# R7FA8M1AH register map
Vendor: Renesas; Series: RA8; File version: 1.2
CPU: CM85 r0p0, little endian, MPU, FPU, VTOR, 4 interrupt priority bits
Registers are 32-bit, read-write, reset 0x0 unless marked. A register's access mark holds for its fields unless they carry their own. Offsets are from the block's base; [hi:lo] are bit positions; {n}, {i} and the like mark numbered series; 'fields as' and 'values as' point back to an identical list; <NAME> marks a mode.

## I3C (part 3 of 4) — I2C I3C unified IP
Base 0x4035F000
Same registers: I3C_NS 0x5035F000
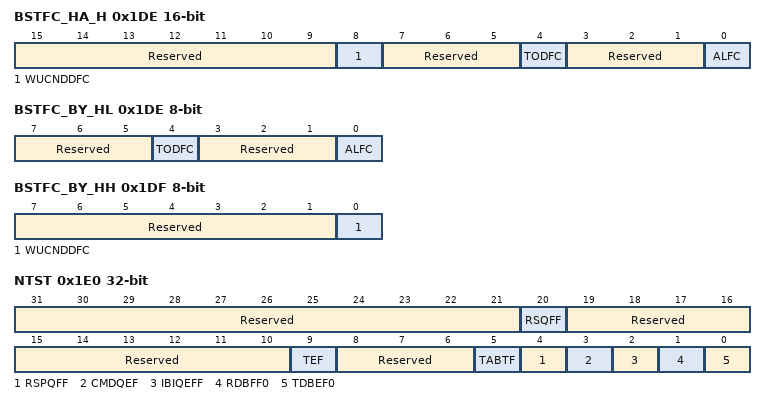
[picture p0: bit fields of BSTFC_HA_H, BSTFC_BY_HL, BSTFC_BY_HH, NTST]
0x1DE BSTFC_HA_H 16-bit wo — Bus Status Force Register
  [15:9] Reserved — The write value should be 0000000.
  [8] WUCNDDFC — Wake-Up Condition Detection Force
    0=not Force Wake-Up Condition Detection Interrupt for software testing; 1=Force Wake-Up Condition Detection Interrupt for software testing
  [7:5] Reserved — The write value should be 000.
  [4] TODFC — Timeout Detection Force
    0=not Force Timeout Detection Interrupt for software testing; 1=Force Timeout Detection Interrupt for software testing
  [3:1] Reserved — The write value should be 000.
  [0] ALFC — Arbitration Lost Force
    0=not Force Arbitration Lost Interrupt for software testing; 1=Force Arbitration Lost Interrupt for software testing
0x1DE BSTFC_BY_HL 8-bit wo — Bus Status Force Register
  [7:5] Reserved — The write value should be 000.
  [4] TODFC — Timeout Detection Force
    values as BSTFC_HA_H.TODFC
  [3:1] Reserved — The write value should be 000.
  [0] ALFC — Arbitration Lost Force
    values as BSTFC_HA_H.ALFC
0x1DF BSTFC_BY_HH 8-bit wo — Bus Status Force Register
  [7:1] Reserved — The write value should be 0000000.
  [0] WUCNDDFC — Wake-Up Condition Detection Force
    values as BSTFC_HA_H.WUCNDDFC
0x1E0 NTST — Normal Transfer Status Register
  [31:21] Reserved — These bits are read as 00000000000. The write value should be 00000000000.
  [20] RSQFF read-modifies — Normal Receive Status Queue Full Flag
    0=The number of Receive Status Queue entries is <= the NRQTHCTL.RSQTH threshold; 1=The number of Receive Status Queue entries is > the NRQTHCTL.RSQTH threshold
  [19:10] Reserved — These bits are read as 0000000000. The write value should be 0000000000.
  [9] TEF read-modifies — Normal Transfer Error Flag
    0=Transfer Error does not occur; 1=Transfer Error occurs
  [8:6] Reserved — These bits are read as 000. The write value should be 000.
  [5] TABTF read-modifies — Normal Transfer Abort Flag
    0=Transfer Abort does not occur; 1=Transfer Abort occur
  [4] RSPQFF read-modifies — Normal Response Queue Full Flag
    0=The number of Response Queue entries is <= the NQTHCTL.RSPQTH threshold; 1=The number of Response Queue entries is > the NQTHCTL.RSPQTH threshold
  [3] CMDQEF read-modifies — Normal Command Queue Empty Flag
    0=The number of Command Queue empties is < the Command Queue size; 1=The number of Command Queue empties is the Command Queue size; 0=The number of Command Queue empties is < the NQTHCTL.CMDQTH threshold; 1=The number of Command Queue empties is >= the NQTHCTL.CMDQTH threshold
  [2] IBIQEFF read-modifies — Normal IBI Queue Empty/Full Flag
    0=The number of IBI Status Queue entries is <= the NQTHCTL.IBIQTH threshold; 1=The number of IBI Status Queue entries is > the NQTHCTL.IBIQTH threshold; 0=The number of IBI Data Buffer empties is < the IBI Data Buffer size; 1=The number of IBI Data Buffer empties is the IBI Data Buffer size; 0=The number of IBI Data Buffer empties is < the NQTHCTL.IBIQTH threshold; 1=The number of IBI Data Buffer empties is >= the NQTHCTL.IBIQTH threshold
  [1] RDBFF0 read-modifies — Normal Rx Data Buffer Full Flag 0
    0=Normal Rx Data Buffer0 contains no receive data; 1=Normal Rx Data Buffer0 contains receive data; 0=The number of entries in the Normal Rx Data Buffer 0 is < the NTBTHCTL0.RXDBTH[2:0] threshold; 1=The number of entries in the Normal Rx Data Buffer 0 is >= the NTBTHCTL0.RXDBTH[2:0] threshold
  [0] TDBEF0 read-modifies — Normal Tx Data Buffer Empty Flag 0
    0=Normal Tx Data Buffer 0 contains transmit data; 1=Normal Tx Data Buffer 0 contains no transmit data; 0=The number of empties in the Normal Tx Data Buffer 0 is < the NTBTHCTL0.TXDBTH[2:0] threshold; 1=The number of empties in the Normal Tx Data Buffer 0 is >= the NTBTHCTL0.TXDBTH[2:0] threshold
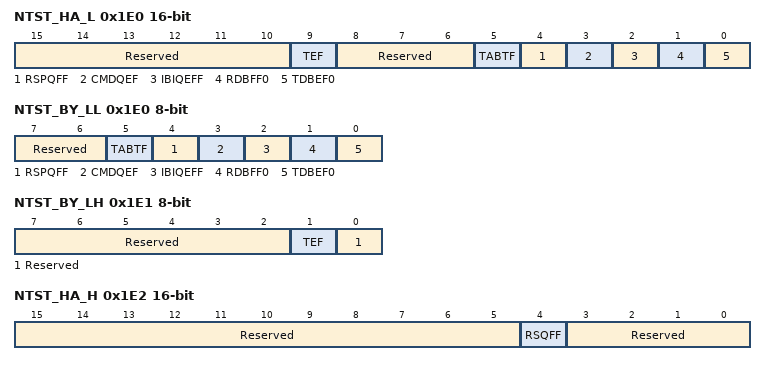
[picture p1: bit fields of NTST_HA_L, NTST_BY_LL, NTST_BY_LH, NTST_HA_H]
0x1E0 NTST_HA_L 16-bit — Normal Transfer Status Register
  [15:10] Reserved — These bits are read as 000000. The write value should be 000000.
  [9] TEF read-modifies — Normal Transfer Error Flag
    0=Transfer Error does not occur; 1=Transfer Error occurs
  [8:6] Reserved — These bits are read as 000. The write value should be 000.
  [5] TABTF read-modifies — Normal Transfer Abort Flag
    0=Transfer Abort does not occur; 1=Transfer Abort occur
  [4] RSPQFF read-modifies — Normal Response Queue Full Flag
    values as NTST.RSPQFF
  [3] CMDQEF read-modifies — Normal Command Queue Empty Flag
    values as NTST.CMDQEF
  [2] IBIQEFF read-modifies — Normal IBI Queue Empty/Full Flag
    values as NTST.IBIQEFF
  [1] RDBFF0 read-modifies — Normal Rx Data Buffer Full Flag 0
    values as NTST.RDBFF0
  [0] TDBEF0 read-modifies — Normal Tx Data Buffer Empty Flag 0
    values as NTST.TDBEF0
0x1E0 NTST_BY_LL 8-bit — Normal Transfer Status Register
  [7:6] Reserved — These bits are read as 00. The write value should be 00.
  [5] TABTF read-modifies — Normal Transfer Abort Flag
    0=Transfer Abort does not occur; 1=Transfer Abort occur
  [4] RSPQFF read-modifies — Normal Response Queue Full Flag
    values as NTST.RSPQFF
  [3] CMDQEF read-modifies — Normal Command Queue Empty Flag
    values as NTST.CMDQEF
  [2] IBIQEFF read-modifies — Normal IBI Queue Empty/Full Flag
    values as NTST.IBIQEFF
  [1] RDBFF0 read-modifies — Normal Rx Data Buffer Full Flag 0
    values as NTST.RDBFF0
  [0] TDBEF0 read-modifies — Normal Tx Data Buffer Empty Flag 0
    values as NTST.TDBEF0
0x1E1 NTST_BY_LH 8-bit — Normal Transfer Status Register
  [7:2] Reserved — These bits are read as 000000. The write value should be 000000.
  [1] TEF read-modifies — Normal Transfer Error Flag
    0=Transfer Error does not occur; 1=Transfer Error occurs
  [0] Reserved — This bit is read as 0. The write value should be 0.
0x1E2 NTST_HA_H 16-bit — Normal Transfer Status Register
  [15:5] Reserved — These bits are read as 00000000000. The write value should be 00000000000.
  [4] RSQFF read-modifies — Normal Receive Status Queue Full Flag
    values as NTST.RSQFF
  [3:0] Reserved — These bits are read as 0000. The write value should be 0000.
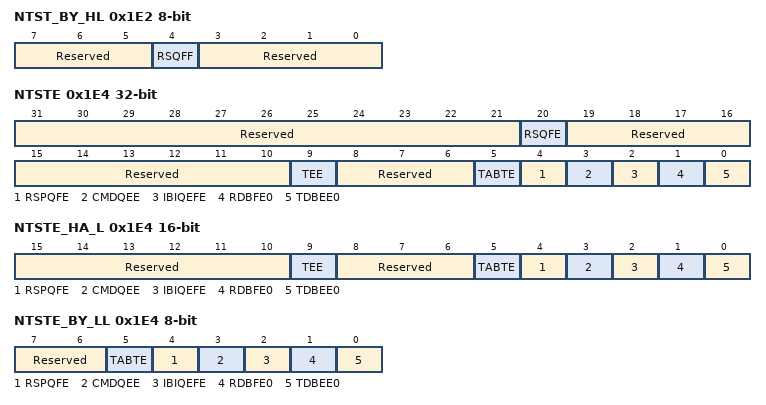
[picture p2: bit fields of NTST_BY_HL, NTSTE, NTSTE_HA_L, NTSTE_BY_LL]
0x1E2 NTST_BY_HL 8-bit — Normal Transfer Status Register
  [7:5] Reserved — These bits are read as 000. The write value should be 000.
  [4] RSQFF read-modifies — Normal Receive Status Queue Full Flag
    values as NTST.RSQFF
  [3:0] Reserved — These bits are read as 0000. The write value should be 0000.
0x1E4 NTSTE — Normal Transfer Status Enable Register
  [31:21] Reserved — These bits are read as 00000000000. The write value should be 00000000000.
  [20] RSQFE — Normal Receive Status Queue Full Enable
    0=Disables Receive Status Buffer Full Interrupt Status logging; 1=Enables Receive Status Buffer Full Interrupt Status logging
  [19:10] Reserved — These bits are read as 0000000000. The write value should be 0000000000.
  [9] TEE — Normal Transfer Error Enable
    0=Disables Transfer Error Interrupt Status logging; 1=Enables Transfer Error Interrupt Status logging
  [8:6] Reserved — These bits are read as 000. The write value should be 000.
  [5] TABTE — Normal Transfer Abort Enable
    0=Disables Transfer Abort Interrupt Status logging; 1=Enables Transfer Abort Interrupt Status logging
  [4] RSPQFE — Normal Response Queue Full Enable
    0=Disables Response Buffer Full Interrupt Status logging; 1=Enables Response Buffer Full Interrupt Status logging
  [3] CMDQEE — Normal Command Queue Empty Enable
    0=Disables Command Buffer Empty Interrupt Status logging; 1=Enables Command Buffer Empty Interrupt Status logging
  [2] IBIQEFE — Normal IBI Queue Empty/Full Enable
    0=Disables IBI Status Buffer Empty/Full Interrupt Status logging; 1=Enables IBI Status Buffer Empty/Full Interrupt Status logging
  [1] RDBFE0 — Normal Rx Data Buffer Full Enable 0
    0=Disables Rx0 Data Buffer Full Interrupt Status logging; 1=Enables Rx0 Data Buffer Full Interrupt Status logging
  [0] TDBEE0 — Normal Tx Data Buffer Empty Enable 0
    0=Disables Tx0 Data Buffer Empty Interrupt Status logging; 1=Enables Tx0 Data Buffer Empty Interrupt Status logging
0x1E4 NTSTE_HA_L 16-bit — Normal Transfer Status Enable Register
  [15:10] Reserved — These bits are read as 000000. The write value should be 000000.
  [9] TEE — Normal Transfer Error Enable
    values as NTSTE.TEE
  [8:6] Reserved — These bits are read as 000. The write value should be 000.
  [5] TABTE — Normal Transfer Abort Enable
    values as NTSTE.TABTE
  [4] RSPQFE — Normal Response Queue Full Enable
    values as NTSTE.RSPQFE
  [3] CMDQEE — Normal Command Queue Empty Enable
    values as NTSTE.CMDQEE
  [2] IBIQEFE — Normal IBI Queue Empty/Full Enable
    values as NTSTE.IBIQEFE
  [1] RDBFE0 — Normal Rx Data Buffer Full Enable 0
    values as NTSTE.RDBFE0
  [0] TDBEE0 — Normal Tx Data Buffer Empty Enable 0
    values as NTSTE.TDBEE0
0x1E4 NTSTE_BY_LL 8-bit — Normal Transfer Status Enable Register
  [7:6] Reserved — These bits are read as 00. The write value should be 00.
  [5] TABTE — Normal Transfer Abort Enable
    values as NTSTE.TABTE
  [4] RSPQFE — Normal Response Queue Full Enable
    values as NTSTE.RSPQFE
  [3] CMDQEE — Normal Command Queue Empty Enable
    values as NTSTE.CMDQEE
  [2] IBIQEFE — Normal IBI Queue Empty/Full Enable
    values as NTSTE.IBIQEFE
  [1] RDBFE0 — Normal Rx Data Buffer Full Enable 0
    values as NTSTE.RDBFE0
  [0] TDBEE0 — Normal Tx Data Buffer Empty Enable 0
    values as NTSTE.TDBEE0
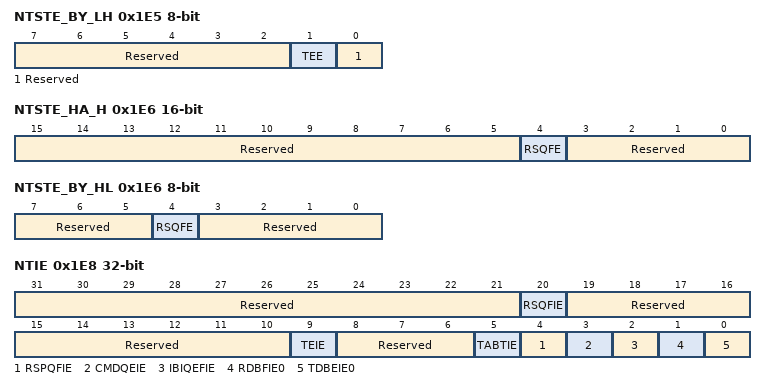
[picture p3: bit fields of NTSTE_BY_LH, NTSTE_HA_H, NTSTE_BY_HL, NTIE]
0x1E5 NTSTE_BY_LH 8-bit — Normal Transfer Status Enable Register
  [7:2] Reserved — These bits are read as 000000. The write value should be 000000.
  [1] TEE — Normal Transfer Error Enable
    values as NTSTE.TEE
  [0] Reserved — This bit is read as 0. The write value should be 0.
0x1E6 NTSTE_HA_H 16-bit — Normal Transfer Status Enable Register
  [15:5] Reserved — These bits are read as 00000000000. The write value should be 00000000000.
  [4] RSQFE — Normal Receive Status Queue Full Enable
    values as NTSTE.RSQFE
  [3:0] Reserved — These bits are read as 0000. The write value should be 0000.
0x1E6 NTSTE_BY_HL 8-bit — Normal Transfer Status Enable Register
  [7:5] Reserved — These bits are read as 000. The write value should be 000.
  [4] RSQFE — Normal Receive Status Queue Full Enable
    values as NTSTE.RSQFE
  [3:0] Reserved — These bits are read as 0000. The write value should be 0000.
0x1E8 NTIE — Normal Transfer Interrupt Enable Register
  [31:21] Reserved — These bits are read as 00000000000. The write value should be 00000000000.
  [20] RSQFIE — Normal Receive Status Queue Full Interrupt Enable
    0=Disables Receive Status Buffer Full Interrupt Signal; 1=Enables Receive Status Buffer Full Interrupt Signal
  [19:10] Reserved — These bits are read as 0000000000. The write value should be 0000000000.
  [9] TEIE — Normal Transfer Error Interrupt Enable
    0=Disables Transfer Error Interrupt Signal; 1=Enables Transfer Error Interrupt Signal
  [8:6] Reserved — These bits are read as 000. The write value should be 000.
  [5] TABTIE — Normal Transfer Abort Interrupt Enable
    0=Disables Transfer Abort Interrupt Signal; 1=Enables Transfer Abort Interrupt Signal
  [4] RSPQFIE — Normal Response Queue Full Interrupt Enable
    0=Disables Response Buffer Full Interrupt Signal; 1=Enables Response Buffer Full Interrupt Signal
  [3] CMDQEIE — Normal Command Queue Empty Interrupt Enable
    0=Disables Command Buffer Empty Interrupt Signal; 1=Enables Command Buffer Empty Interrupt Signal
  [2] IBIQEFIE — Normal IBI Queue Empty/Full Interrupt Enable
    0=Disables IBI Status Buffer Empty/Full Interrupt Signal; 1=Enables IBI Status Buffer Empty/Full Interrupt Signal
  [1] RDBFIE0 — Normal Rx Data Buffer Full Interrupt Enable 0
    0=Disables Rx0 Data Buffer Full Interrupt Signal; 1=Enables Rx0 Data Buffer Full Interrupt Signal
  [0] TDBEIE0 — Normal Tx Data Buffer Empty Interrupt Enable 0
    0=Disables Tx0 Data Buffer Empty Interrupt Signal; 1=Enables Tx0 Data Buffer Empty Interrupt Signal
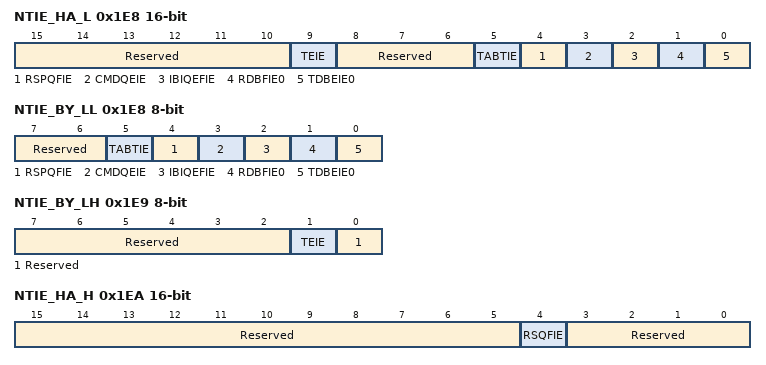
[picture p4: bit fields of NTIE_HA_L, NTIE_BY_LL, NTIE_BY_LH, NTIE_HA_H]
0x1E8 NTIE_HA_L 16-bit — Normal Transfer Interrupt Enable Register
  [15:10] Reserved — These bits are read as 000000. The write value should be 000000.
  [9] TEIE — Normal Transfer Error Interrupt Enable
    values as NTIE.TEIE
  [8:6] Reserved — These bits are read as 000. The write value should be 000.
  [5] TABTIE — Normal Transfer Abort Interrupt Enable
    values as NTIE.TABTIE
  [4] RSPQFIE — Normal Response Queue Full Interrupt Enable
    values as NTIE.RSPQFIE
  [3] CMDQEIE — Normal Command Queue Empty Interrupt Enable
    values as NTIE.CMDQEIE
  [2] IBIQEFIE — Normal IBI Queue Empty/Full Interrupt Enable
    values as NTIE.IBIQEFIE
  [1] RDBFIE0 — Normal Rx Data Buffer Full Interrupt Enable 0
    values as NTIE.RDBFIE0
  [0] TDBEIE0 — Normal Tx Data Buffer Empty Interrupt Enable 0
    values as NTIE.TDBEIE0
0x1E8 NTIE_BY_LL 8-bit — Normal Transfer Interrupt Enable Register
  [7:6] Reserved — These bits are read as 00. The write value should be 00.
  [5] TABTIE — Normal Transfer Abort Interrupt Enable
    values as NTIE.TABTIE
  [4] RSPQFIE — Normal Response Queue Full Interrupt Enable
    values as NTIE.RSPQFIE
  [3] CMDQEIE — Normal Command Queue Empty Interrupt Enable
    values as NTIE.CMDQEIE
  [2] IBIQEFIE — Normal IBI Queue Empty/Full Interrupt Enable
    values as NTIE.IBIQEFIE
  [1] RDBFIE0 — Normal Rx Data Buffer Full Interrupt Enable 0
    values as NTIE.RDBFIE0
  [0] TDBEIE0 — Normal Tx Data Buffer Empty Interrupt Enable 0
    values as NTIE.TDBEIE0
0x1E9 NTIE_BY_LH 8-bit — Normal Transfer Interrupt Enable Register
  [7:2] Reserved — These bits are read as 000000. The write value should be 000000.
  [1] TEIE — Normal Transfer Error Interrupt Enable
    values as NTIE.TEIE
  [0] Reserved — This bit is read as 0. The write value should be 0.
0x1EA NTIE_HA_H 16-bit — Normal Transfer Interrupt Enable Register
  [15:5] Reserved — These bits are read as 00000000000. The write value should be 00000000000.
  [4] RSQFIE — Normal Receive Status Queue Full Interrupt Enable
    values as NTIE.RSQFIE
  [3:0] Reserved — These bits are read as 0000. The write value should be 0000.
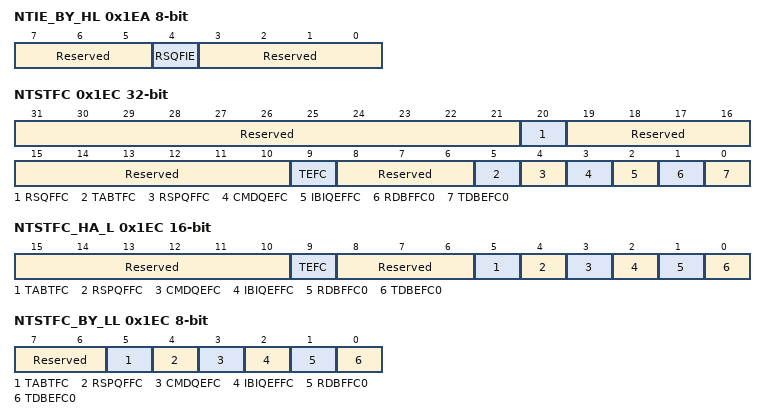
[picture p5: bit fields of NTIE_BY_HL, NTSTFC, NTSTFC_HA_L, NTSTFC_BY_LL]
0x1EA NTIE_BY_HL 8-bit — Normal Transfer Interrupt Enable Register
  [7:5] Reserved — These bits are read as 000. The write value should be 000.
  [4] RSQFIE — Normal Receive Status Queue Full Interrupt Enable
    values as NTIE.RSQFIE
  [3:0] Reserved — These bits are read as 0000. The write value should be 0000.
0x1EC NTSTFC wo — Normal Transfer Status Force Register
  [31:21] Reserved — The write value should be 00000000000.
  [20] RSQFFC — Normal Receive Status Queue Full Force
    0=not Force Receive Status Buffer Full Interrupt for software testing; 1=Force Receive Status Buffer Full Interrupt for software testing
  [19:10] Reserved — The write value should be 0000000000.
  [9] TEFC — Normal Transfer Error Force
    0=not Force Transfer Error Interrupt for software testing; 1=Force Transfer Error Interrupt for software testing
  [8:6] Reserved — The write value should be 000.
  [5] TABTFC — Normal Transfer Abort Force
    0=not Force Transfer Abort Interrupt for software testing; 1=Force Transfer Abort Interrupt for software testing
  [4] RSPQFFC — Normal Response Queue Full Force
    0=not Force Response Buffer Full Interrupt for software testing; 1=Force Response Buffer Full Interrupt for software testing
  [3] CMDQEFC — Normal Command Queue Empty Force
    0=not Force Command Buffer Empty Interrupt for software testing; 1=Force Command Buffer Empty Interrupt for software testing
  [2] IBIQEFFC — Normal IBI Queue Empty/Full Force
    0=not Force IBI Status Buffer Empty/Full Interrupt for software testing; 1=Force IBI Status Buffer Empty/Full Interrupt for software testing
  [1] RDBFFC0 — Normal Rx Data Buffer Full Force 0
    0=not Force Rx0 Data Buffer Full Interrupt for software testing; 1=Force Rx0 Data Buffer Full Interrupt for software testing
  [0] TDBEFC0 — Normal Tx Data Buffer Empty Force 0
    0=not Force Tx0 Data Buffer Empty Interrupt for software testing; 1=Force Tx0 Data Buffer Empty Interrupt for software testing
0x1EC NTSTFC_HA_L 16-bit wo — Normal Transfer Status Force Register
  [15:10] Reserved — The write value should be 000000.
  [9] TEFC — Normal Transfer Error Force
    values as NTSTFC.TEFC
  [8:6] Reserved — The write value should be 000.
  [5] TABTFC — Normal Transfer Abort Force
    values as NTSTFC.TABTFC
  [4] RSPQFFC — Normal Response Queue Full Force
    values as NTSTFC.RSPQFFC
  [3] CMDQEFC — Normal Command Queue Empty Force
    values as NTSTFC.CMDQEFC
  [2] IBIQEFFC — Normal IBI Queue Empty/Full Force
    values as NTSTFC.IBIQEFFC
  [1] RDBFFC0 — Normal Rx Data Buffer Full Force 0
    values as NTSTFC.RDBFFC0
  [0] TDBEFC0 — Normal Tx Data Buffer Empty Force 0
    values as NTSTFC.TDBEFC0
0x1EC NTSTFC_BY_LL 8-bit wo — Normal Transfer Status Force Register
  [7:6] Reserved — The write value should be 00.
  [5] TABTFC — Normal Transfer Abort Force
    values as NTSTFC.TABTFC
  [4] RSPQFFC — Normal Response Queue Full Force
    values as NTSTFC.RSPQFFC
  [3] CMDQEFC — Normal Command Queue Empty Force
    values as NTSTFC.CMDQEFC
  [2] IBIQEFFC — Normal IBI Queue Empty/Full Force
    values as NTSTFC.IBIQEFFC
  [1] RDBFFC0 — Normal Rx Data Buffer Full Force 0
    values as NTSTFC.RDBFFC0
  [0] TDBEFC0 — Normal Tx Data Buffer Empty Force 0
    values as NTSTFC.TDBEFC0
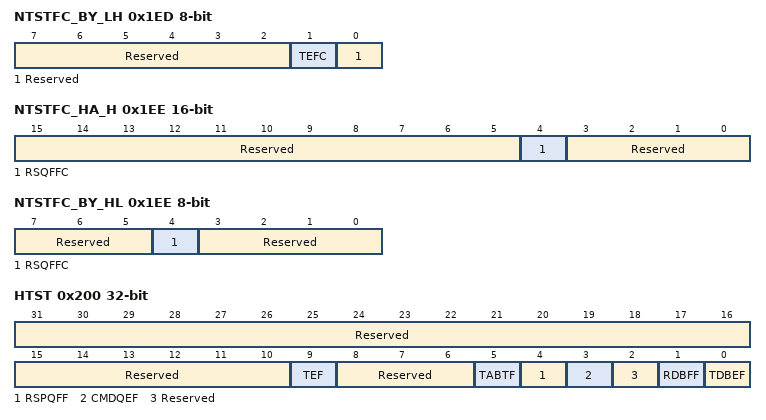
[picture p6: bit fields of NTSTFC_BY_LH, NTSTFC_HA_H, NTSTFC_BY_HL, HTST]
0x1ED NTSTFC_BY_LH 8-bit wo — Normal Transfer Status Force Register
  [7:2] Reserved — The write value should be 000000.
  [1] TEFC — Normal Transfer Error Force
    values as NTSTFC.TEFC
  [0] Reserved — The write value should be 0.
0x1EE NTSTFC_HA_H 16-bit wo — Normal Transfer Status Force Register
  [15:5] Reserved — The write value should be 00000000000.
  [4] RSQFFC — Normal Receive Status Queue Full Force
    values as NTSTFC.RSQFFC
  [3:0] Reserved — The write value should be 0000.
0x1EE NTSTFC_BY_HL 8-bit wo — Normal Transfer Status Force Register
  [7:5] Reserved — The write value should be 000.
  [4] RSQFFC — Normal Receive Status Queue Full Force
    values as NTSTFC.RSQFFC
  [3:0] Reserved — The write value should be 0000.
0x200 HTST — High Priority Transfer Status Register
  [31:10] Reserved — These bits are read as 0000000000000000000000. The write value should be 0000000000000000000000.
  [9] TEF read-modifies — High Priority Transfer Error Flag
    0=High Priority Transfer Error does not occur; 1=High Priority Transfer Error occurs
  [8:6] Reserved — These bits are read as 000. The write value should be 000.
  [5] TABTF read-modifies — High Priority Transfer Abort Flag
    0=High Priority Transfer Abort does not occur; 1=High Priority Transfer Abort occurs
  [4] RSPQFF read-modifies — High Priority Response Queue Full Flag
    0=The number of High Priority Response Queue entries is <= the HQTHCTL .RSPQTH threshold; 1=The number of High Priority Response Queue entries is > the HQTHCTL .RSPQTH threshold
  [3] CMDQEF read-modifies — High Priority Command Queue Empty Flag
    0=The number of Command Queue empties is < the Command Queue size; 1=The number of Command Queue empties is the Command Queue size; 0=The number of High Priority Command Queue empties is < the HQTHCTL.CMDQTH threshold; 1=The number of High Priority Command Queue empties is >= the HQTHCTL.CMDQTH threshold
  [2] Reserved — This bit is read as 0. The write value should be 0.
  [1] RDBFF read-modifies — High Priority Rx Data Buffer Full Flag
    0=The number of entries in the High Priority Rx Data Buffer is < the HTBTHCTL.RXDBTH[2:0] threshold; 1=The number of entries in the High Priority Rx Data Buffer is >= the HTBTHCTL.RXDBTH[2:0] threshold
  [0] TDBEF read-modifies — High Priority Tx Data Buffer Empty Flag
    0=The number of empties in the High Priority Tx Data Buffer is < the HTBTHCTL.TXDBTH[2:0] threshold; 1=The number of empties in the High Priority Tx Data Buffer is >= the HTBTHCTL.TXDBTH[2:0] threshold
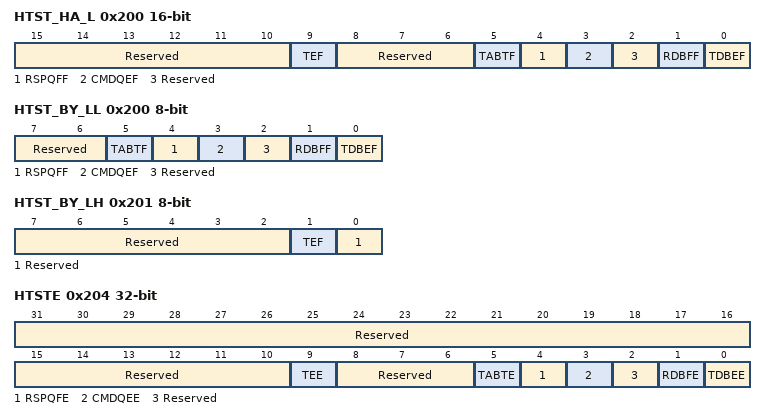
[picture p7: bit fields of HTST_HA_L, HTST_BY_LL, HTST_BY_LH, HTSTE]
0x200 HTST_HA_L 16-bit — High Priority Transfer Status Register
  [15:10] Reserved — These bits are read as 000000. The write value should be 000000.
  [9] TEF read-modifies — High Priority Transfer Error Flag
    values as HTST.TEF
  [8:6] Reserved — These bits are read as 000. The write value should be 000.
  [5] TABTF read-modifies — High Priority Transfer Abort Flag
    values as HTST.TABTF
  [4] RSPQFF read-modifies — High Priority Response Queue Full Flag
    values as HTST.RSPQFF
  [3] CMDQEF read-modifies — High Priority Command Queue Empty Flag
    values as HTST.CMDQEF
  [2] Reserved — This bit is read as 0. The write value should be 0.
  [1] RDBFF read-modifies — High Priority Rx Data Buffer Full Flag
    values as HTST.RDBFF
  [0] TDBEF read-modifies — High Priority Tx Data Buffer Empty Flag
    values as HTST.TDBEF
0x200 HTST_BY_LL 8-bit — High Priority Transfer Status Register
  [7:6] Reserved — These bits are read as 00. The write value should be 00.
  [5] TABTF read-modifies — High Priority Transfer Abort Flag
    values as HTST.TABTF
  [4] RSPQFF read-modifies — High Priority Response Queue Full Flag
    values as HTST.RSPQFF
  [3] CMDQEF read-modifies — High Priority Command Queue Empty Flag
    values as HTST.CMDQEF
  [2] Reserved — This bit is read as 0. The write value should be 0.
  [1] RDBFF read-modifies — High Priority Rx Data Buffer Full Flag
    values as HTST.RDBFF
  [0] TDBEF read-modifies — High Priority Tx Data Buffer Empty Flag
    values as HTST.TDBEF
0x201 HTST_BY_LH 8-bit — High Priority Transfer Status Register
  [7:2] Reserved — These bits are read as 000000. The write value should be 000000.
  [1] TEF read-modifies — High Priority Transfer Error Flag
    values as HTST.TEF
  [0] Reserved — This bit is read as 0. The write value should be 0.
0x204 HTSTE — High Priority Transfer Status Enable Register
  [31:10] Reserved — These bits are read as 0000000000000000000000. The write value should be 0000000000000000000000.
  [9] TEE — High Priority Transfer Error Enable
    0=Disables High Priority Transfer Error interrupt Stats logging; 1=Enables High Priority Transfer Error interrupt Stats logging
  [8:6] Reserved — These bits are read as 000. The write value should be 000.
  [5] TABTE — High Priority Transfer Abort Enable
    0=Disables High PriorityTransfer Abort Interrupt Status logging; 1=Enables High Priority Transfer Abort Interrupt Status logging
  [4] RSPQFE — High Priority Response Queue Full Enable
    0=Disables High Priority Response Buffer Full Interrupt Status logging; 1=Enables High Priority Response Buffer Full Interrupt Status logging
  [3] CMDQEE — High Priority Command Queue Empty Enable.
    0=Disables High Priority Command Buffer Empty Interrupt Status logging; 1=Enables High Priority Command Buffer Empty Interrupt Status logging
  [2] Reserved — This bit is read as 0. The write value should be 0.
  [1] RDBFE — High Priority Rx Data Buffer Full Enable
    0=Disables High Priority Rx Data Buffer Full Interrupt Status logging; 1=Enables High Priority Rx Data Buffer Full Interrupt Status logging
  [0] TDBEE — High Priority Tx Data Buffer Empty Enable
    0=Disables High Priority Tx Data Buffer Empty Interrupt Status logging; 1=Enables High Priority Tx Data Buffer Empty Interrupt Status logging
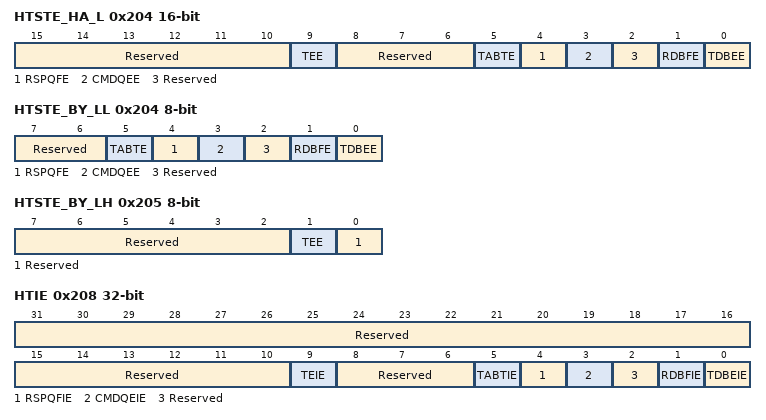
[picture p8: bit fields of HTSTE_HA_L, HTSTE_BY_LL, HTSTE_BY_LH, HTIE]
0x204 HTSTE_HA_L 16-bit — High Priority Transfer Status Enable Register
  [15:10] Reserved — These bits are read as 000000. The write value should be 000000.
  [9] TEE — High Priority Transfer Error Enable
    values as HTSTE.TEE
  [8:6] Reserved — These bits are read as 000. The write value should be 000.
  [5] TABTE — High Priority Transfer Abort Enable
    values as HTSTE.TABTE
  [4] RSPQFE — High Priority Response Queue Full Enable
    values as HTSTE.RSPQFE
  [3] CMDQEE — High Priority Command Queue Empty Enable.
    values as HTSTE.CMDQEE
  [2] Reserved — This bit is read as 0. The write value should be 0.
  [1] RDBFE — High Priority Rx Data Buffer Full Enable
    values as HTSTE.RDBFE
  [0] TDBEE — High Priority Tx Data Buffer Empty Enable
    values as HTSTE.TDBEE
0x204 HTSTE_BY_LL 8-bit — High Priority Transfer Status Enable Register
  [7:6] Reserved — These bits are read as 00. The write value should be 00.
  [5] TABTE — High Priority Transfer Abort Enable
    values as HTSTE.TABTE
  [4] RSPQFE — High Priority Response Queue Full Enable
    values as HTSTE.RSPQFE
  [3] CMDQEE — High Priority Command Queue Empty Enable.
    values as HTSTE.CMDQEE
  [2] Reserved — This bit is read as 0. The write value should be 0.
  [1] RDBFE — High Priority Rx Data Buffer Full Enable
    values as HTSTE.RDBFE
  [0] TDBEE — High Priority Tx Data Buffer Empty Enable
    values as HTSTE.TDBEE
0x205 HTSTE_BY_LH 8-bit — High Priority Transfer Status Enable Register
  [7:2] Reserved — These bits are read as 000000. The write value should be 000000.
  [1] TEE — High Priority Transfer Error Enable
    values as HTSTE.TEE
  [0] Reserved — This bit is read as 0. The write value should be 0.
0x208 HTIE — High Priority Transfer Interrupt Enable Register
  [31:10] Reserved — These bits are read as 0000000000000000000000. The write value should be 0000000000000000000000.
  [9] TEIE — High Priority Transfer Error Interrupt Enable
    0=Disables High Priority Transfer Error Interrupt Signal; 1=Enables High Priority Transfer Error Interrupt Signal
  [8:6] Reserved — These bits are read as 000. The write value should be 000.
  [5] TABTIE — High Priority Transfer Abort Interrupt Enable
    0=Disables High Priority Transfer Abort interrupt Signal; 1=Enables High Priority Transfer Abort interrupt Signal
  [4] RSPQFIE — High Priority Response Queue Full Interrupt Enable
    0=Disables High Priority Response Buffer Full Interrupt Signal; 1=Enables High Priority Response Buffer Full Interrupt Signal
  [3] CMDQEIE — High Priority Command Queue Empty Interrupt Enable
    0=Disables High Priority Command Buffer Empty Interrupt Signal; 1=Enables High Priority Command Buffer Empty Interrupt Signal
  [2] Reserved — This bit is read as 0. The write value should be 0.
  [1] RDBFIE — High Priority Rx Data Buffer Full Interrupt Enable
    0=Disables High Priority Rx Data Buffer Full Interrupt Signal; 1=Enables High Priority Rx Data Buffer Full Interrupt Signal
  [0] TDBEIE — High Priority Tx Data Buffer Empty Interrupt Enable
    0=Disables High Priority Tx Data Buffer Empty Interrupt Signal; 1=Enables High Priority Tx Data Buffer Empty Interrupt Signal
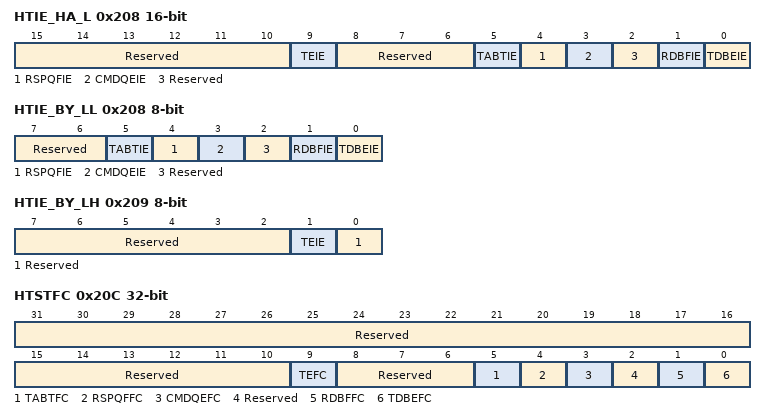
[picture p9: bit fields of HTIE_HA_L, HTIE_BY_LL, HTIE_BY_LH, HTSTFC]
0x208 HTIE_HA_L 16-bit — High Priority Transfer Interrupt Enable Register
  [15:10] Reserved — These bits are read as 000000. The write value should be 000000.
  [9] TEIE — High Priority Transfer Error Interrupt Enable
    values as HTIE.TEIE
  [8:6] Reserved — These bits are read as 000. The write value should be 000.
  [5] TABTIE — High Priority Transfer Abort Interrupt Enable
    values as HTIE.TABTIE
  [4] RSPQFIE — High Priority Response Queue Full Interrupt Enable
    values as HTIE.RSPQFIE
  [3] CMDQEIE — High Priority Command Queue Empty Interrupt Enable
    values as HTIE.CMDQEIE
  [2] Reserved — This bit is read as 0. The write value should be 0.
  [1] RDBFIE — High Priority Rx Data Buffer Full Interrupt Enable
    values as HTIE.RDBFIE
  [0] TDBEIE — High Priority Tx Data Buffer Empty Interrupt Enable
    values as HTIE.TDBEIE
0x208 HTIE_BY_LL 8-bit — High Priority Transfer Interrupt Enable Register
  [7:6] Reserved — These bits are read as 00. The write value should be 00.
  [5] TABTIE — High Priority Transfer Abort Interrupt Enable
    values as HTIE.TABTIE
  [4] RSPQFIE — High Priority Response Queue Full Interrupt Enable
    values as HTIE.RSPQFIE
  [3] CMDQEIE — High Priority Command Queue Empty Interrupt Enable
    values as HTIE.CMDQEIE
  [2] Reserved — This bit is read as 0. The write value should be 0.
  [1] RDBFIE — High Priority Rx Data Buffer Full Interrupt Enable
    values as HTIE.RDBFIE
  [0] TDBEIE — High Priority Tx Data Buffer Empty Interrupt Enable
    values as HTIE.TDBEIE
0x209 HTIE_BY_LH 8-bit — High Priority Transfer Interrupt Enable Register
  [7:2] Reserved — These bits are read as 000000. The write value should be 000000.
  [1] TEIE — High Priority Transfer Error Interrupt Enable
    values as HTIE.TEIE
  [0] Reserved — This bit is read as 0. The write value should be 0.
0x20C HTSTFC wo — High Priority Transfer Status Force Register
  [31:10] Reserved — The write value should be 0000000000000000000000.
  [9] TEFC — High Priority Transfer Error Force
    0=not Force High Priority Transfer Error Interrupt for software testing; 1=Force High Priority Transfer Error Interrupt for software testing
  [8:6] Reserved — The write value should be 000.
  [5] TABTFC — High Priority Transfer Abort Force
    0=not Force High Priority Transfer Abort Interrupt for software testing; 1=Force High Priority Transfer Abort Interrupt for software testing
  [4] RSPQFFC — High Priority Response Queue Full Force
    0=not Force High Priority Response Buffer Full Interrupt for software testing; 1=Force High Priority Response Buffer Full Interrupt for software testing
  [3] CMDQEFC — High Priority Command Queue Empty Force
    0=not Force High Priority Command Buffer Empty Interrupt for software testing; 1=Force High Priority Command Buffer Empty Interrupt for software testing
  [2] Reserved — The write value should be 0.
  [1] RDBFFC — High Priority Rx Data Buffer Full Force
    0=not Force High Priority Rx Data Buffer Full Interrupt for software testing; 1=Force High Priority Rx Data Buffer Full Interrupt for software testing
  [0] TDBEFC — High Priority Tx Data Buffer Empty Force
    0=not Force High Priority Tx Data Buffer Empty Interrupt for software testing; 1=Force High Priority Tx Data Buffer Empty Interrupt for software
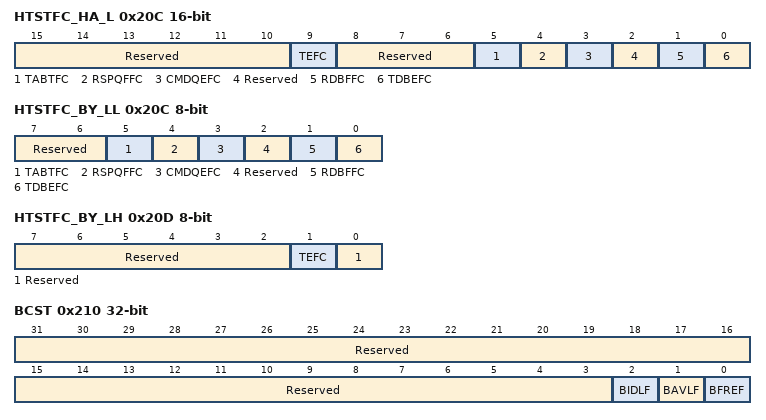
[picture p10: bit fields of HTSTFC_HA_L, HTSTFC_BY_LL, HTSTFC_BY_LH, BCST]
0x20C HTSTFC_HA_L 16-bit wo — High Priority Transfer Status Force Register
  [15:10] Reserved — The write value should be 000000.
  [9] TEFC — High Priority Transfer Error Force
    values as HTSTFC.TEFC
  [8:6] Reserved — The write value should be 000.
  [5] TABTFC — High Priority Transfer Abort Force
    values as HTSTFC.TABTFC
  [4] RSPQFFC — High Priority Response Queue Full Force
    values as HTSTFC.RSPQFFC
  [3] CMDQEFC — High Priority Command Queue Empty Force
    values as HTSTFC.CMDQEFC
  [2] Reserved — The write value should be 0.
  [1] RDBFFC — High Priority Rx Data Buffer Full Force
    values as HTSTFC.RDBFFC
  [0] TDBEFC — High Priority Tx Data Buffer Empty Force
    values as HTSTFC.TDBEFC
0x20C HTSTFC_BY_LL 8-bit wo — High Priority Transfer Status Force Register
  [7:6] Reserved — The write value should be 00.
  [5] TABTFC — High Priority Transfer Abort Force
    values as HTSTFC.TABTFC
  [4] RSPQFFC — High Priority Response Queue Full Force
    values as HTSTFC.RSPQFFC
  [3] CMDQEFC — High Priority Command Queue Empty Force
    values as HTSTFC.CMDQEFC
  [2] Reserved — The write value should be 0.
  [1] RDBFFC — High Priority Rx Data Buffer Full Force
    values as HTSTFC.RDBFFC
  [0] TDBEFC — High Priority Tx Data Buffer Empty Force
    values as HTSTFC.TDBEFC
0x20D HTSTFC_BY_LH 8-bit wo — High Priority Transfer Status Force Register
  [7:2] Reserved — The write value should be 000000.
  [1] TEFC — High Priority Transfer Error Force
    values as HTSTFC.TEFC
  [0] Reserved — The write value should be 0.
0x210 BCST ro — Bus Condition Status Register
  [31:3] Reserved — These bits are read as 00000000000000000000000000000.
  [2] BIDLF — Bus Idle Detection Flag
    0=Have not Detected Bus Idle; 1=Have Detected Bus Idle
  [1] BAVLF — Bus Available Detection Flag
    0=Have not Detected Bus Available; 1=Have Detected Bus Available
  [0] BFREF — Bus Free Detection Flag
    0=Have not Detected Bus Free; 1=Have Detected Bus Free
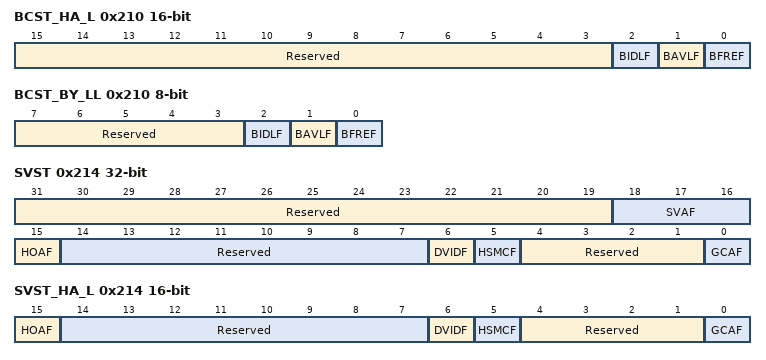
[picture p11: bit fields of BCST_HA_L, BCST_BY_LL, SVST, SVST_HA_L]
0x210 BCST_HA_L 16-bit ro — Bus Condition Status Register
  [15:3] Reserved — These bits are read as 0000000000000.
  [2] BIDLF — Bus Idle Detection Flag
    0=Have not Detected Bus Idle; 1=Have Detected Bus Idle
  [1] BAVLF — Bus Available Detection Flag
    values as BCST.BAVLF
  [0] BFREF — Bus Free Detection Flag
    0=Have not Detected Bus Free; 1=Have Detected Bus Free
0x210 BCST_BY_LL 8-bit ro — Bus Condition Status Register
  [7:3] Reserved — These bits are read as 00000.
  [2] BIDLF — Bus Idle Detection Flag
    0=Have not Detected Bus Idle; 1=Have Detected Bus Idle
  [1] BAVLF — Bus Available Detection Flag
    values as BCST.BAVLF
  [0] BFREF — Bus Free Detection Flag
    0=Have not Detected Bus Free; 1=Have Detected Bus Free
0x214 SVST read-modifies — Slave Status Register
  [31:19] Reserved — These bits are read as 0000000000000. The write value should be 0000000000000.
  [18:16] SVAF read-modifies — Slave Address Detection Flag $x ($x=2 to 0)
    0=Slave{$x} does not detect; 1=Slave{$x} detect
  [15] HOAF read-modifies — Host Address Detection Flag
    0=Host address does not detect; 1=Host address detects
  [14:7] Reserved — These bits are read as 00000000. The write value should be 00000000.
  [6] DVIDF read-modifies — Device-ID Address Detection Flag
    0=Device-ID command does not detect; 1=Device-ID command detects
  [5] HSMCF read-modifies — Hs-mode Master Code Detection Flag
    0=Hs-mode Master Code does not detect; 1=Hs-mode Master Code detects
  [4:1] Reserved — These bits are read as 0000. The write value should be 0000.
  [0] GCAF read-modifies — General Call Address Detection Flag
    0=General call address does not detect; 1=General call address detects
0x214 SVST_HA_L 16-bit read-modifies — Slave Status Register
  [15] HOAF read-modifies — Host Address Detection Flag
    0=Host address does not detect; 1=Host address detects
  [14:7] Reserved — These bits are read as 00000000. The write value should be 00000000.
  [6] DVIDF read-modifies — Device-ID Address Detection Flag
    values as SVST.DVIDF
  [5] HSMCF read-modifies — Hs-mode Master Code Detection Flag
    values as SVST.HSMCF
  [4:1] Reserved — These bits are read as 0000. The write value should be 0000.
  [0] GCAF read-modifies — General Call Address Detection Flag
    values as SVST.GCAF
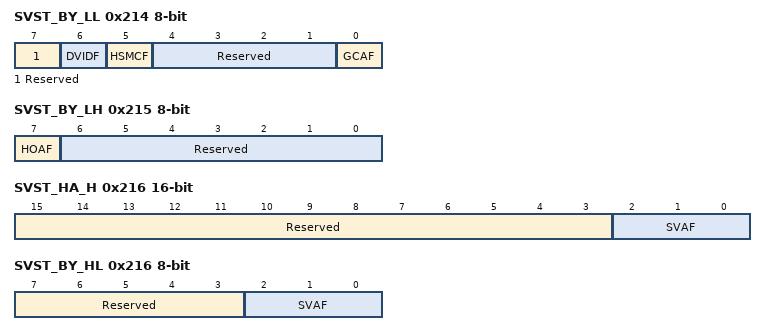
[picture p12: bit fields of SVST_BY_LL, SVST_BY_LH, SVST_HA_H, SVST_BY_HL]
0x214 SVST_BY_LL 8-bit read-modifies — Slave Status Register
  [7] Reserved — This bit is read as 0. The write value should be 0.
  [6] DVIDF read-modifies — Device-ID Address Detection Flag
    values as SVST.DVIDF
  [5] HSMCF read-modifies — Hs-mode Master Code Detection Flag
    values as SVST.HSMCF
  [4:1] Reserved — These bits are read as 0000. The write value should be 0000.
  [0] GCAF read-modifies — General Call Address Detection Flag
    values as SVST.GCAF
0x215 SVST_BY_LH 8-bit read-modifies — Slave Status Register
  [7] HOAF read-modifies — Host Address Detection Flag
    0=Host address does not detect; 1=Host address detects
  [6:0] Reserved — These bits are read as 0000000. The write value should be 0000000.
0x216 SVST_HA_H 16-bit read-modifies — Slave Status Register
  [15:3] Reserved — These bits are read as 0000000000000. The write value should be 0000000000000.
  [2:0] SVAF read-modifies — Slave Address Detection Flag $x ($x=2 to 0)
    0=Slave{$x} does not detect; 1=Slave{$x} detect
0x216 SVST_BY_HL 8-bit read-modifies — Slave Status Register
  [7:3] Reserved — These bits are read as 00000. The write value should be 00000.
  [2:0] SVAF read-modifies — Slave Address Detection Flag $x ($x=2 to 0)
    0=Slave{$x} does not detect; 1=Slave{$x} detect
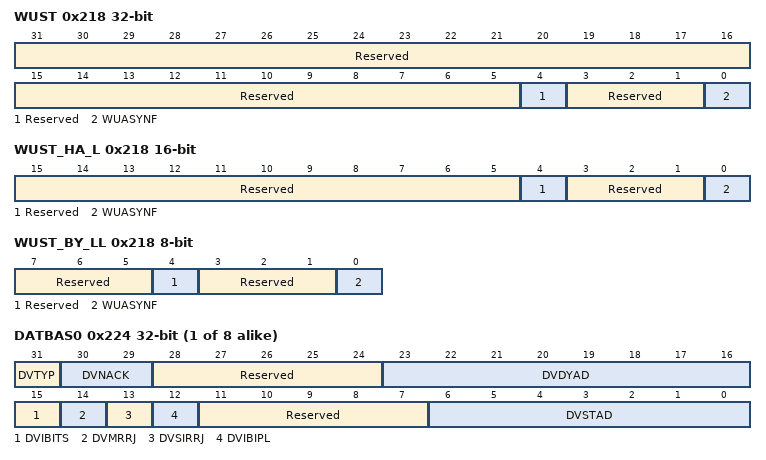
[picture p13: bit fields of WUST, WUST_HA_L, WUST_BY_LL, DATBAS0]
0x218 WUST ro — Wake Up Unit Operating Status Register
  [31:5] Reserved — These bits are read as 000000000000000000000000000.
  [4] Reserved — This bit is read as 0.
  [3:1] Reserved — These bits are read as 000.
  [0] WUASYNF — Wake-Up function Asynchronous operation status Flag
    0=This IP synchronous circuit enable condition; 1=This IP asynchronous circuit enable condition
0x218 WUST_HA_L 16-bit ro — Wake Up Unit Operating Status Register
  [15:5] Reserved — These bits are read as 00000000000.
  [4] Reserved — This bit is read as 0.
  [3:1] Reserved — These bits are read as 000.
  [0] WUASYNF — Wake-Up function Asynchronous operation status Flag
    values as WUST.WUASYNF
0x218 WUST_BY_LL 8-bit ro — Wake Up Unit Operating Status Register
  [7:5] Reserved — These bits are read as 000.
  [4] Reserved — This bit is read as 0.
  [3:1] Reserved — These bits are read as 000.
  [0] WUASYNF — Wake-Up function Asynchronous operation status Flag
    values as WUST.WUASYNF
0x21C MRCCPT ro — MsyncCNT Counter Capture Register
  [31:0] MRCCPT — MSyncCNT Counter Capture
{0x224+8i} DATBAS{i} (i=0..7) — Device Address Table Basic Register {i}
  [31] DVTYP — Device Type
    0=I3C: I3C Device; 1=I2C: I2C Device
  [30:29] DVNACK — Device NACK Retry Count
  [28:24] Reserved — These bits are read as 00000. The write value should be 00000.
  [23:16] DVDYAD — Device I3C Dynamic Address
  [15] DVIBITS — Device IBI Time-stamp
    0=The Master shall not time-stamp IBIs from this Device with Master Time-stamps; 1=The Master shall time-stamp IBIs for this Device with Master Time-stamps
  [14] DVMRRJ — Device In-Band Master Request Reject
    0=This Device shall ACK Master Requests; 1=This Device shall NACK Master Requests and send the auto-disable command
  [13] DVSIRRJ — Device In-Band Slave Interrupt Request Reject
    0=This Device shall ACK the SIR; 1=This Device shall NACK the SIR and send the auto-disable CCC
  [12] DVIBIPL ro — Device IBI Payload
    0=IBIs from this Device do not carry a Data Payload; 1=IBIs from this Device do carry a Data Payload
  [11:7] Reserved — These bits are read as 00000. The write value should be 00000.
  [6:0] DVSTAD — Device Static Address
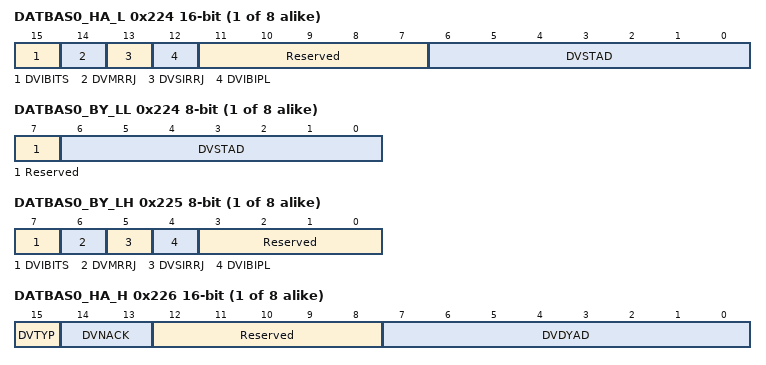
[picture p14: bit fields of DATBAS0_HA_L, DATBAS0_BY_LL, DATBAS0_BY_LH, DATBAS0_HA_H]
{0x224+8i} DATBAS{i}_HA_L 16-bit (i=0..7) — Device Address Table Basic Register {i}
  [15] DVIBITS — Device IBI Time-stamp
    values as DATBAS0.DVIBITS
  [14] DVMRRJ — Device In-Band Master Request Reject
    values as DATBAS0.DVMRRJ
  [13] DVSIRRJ — Device In-Band Slave Interrupt Request Reject
    values as DATBAS0.DVSIRRJ
  [12] DVIBIPL ro — Device IBI Payload
    values as DATBAS0.DVIBIPL
  [11:7] Reserved — These bits are read as 00000. The write value should be 00000.
  [6:0] DVSTAD — Device Static Address
{0x224+8i} DATBAS{i}_BY_LL 8-bit (i=0..7) — Device Address Table Basic Register {i}
  [7] Reserved — This bit is read as 0. The write value should be 0.
  [6:0] DVSTAD — Device Static Address
{0x225+8i} DATBAS{i}_BY_LH 8-bit (i=0..7) — Device Address Table Basic Register {i}
  [7] DVIBITS — Device IBI Time-stamp
    values as DATBAS0.DVIBITS
  [6] DVMRRJ — Device In-Band Master Request Reject
    values as DATBAS0.DVMRRJ
  [5] DVSIRRJ — Device In-Band Slave Interrupt Request Reject
    values as DATBAS0.DVSIRRJ
  [4] DVIBIPL ro — Device IBI Payload
    values as DATBAS0.DVIBIPL
  [3:0] Reserved — These bits are read as 0000. The write value should be 0000.
{0x226+8i} DATBAS{i}_HA_H 16-bit (i=0..7) — Device Address Table Basic Register {i}
  [15] DVTYP — Device Type
    0=I3C: I3C Device; 1=I2C: I2C Device
  [14:13] DVNACK — Device NACK Retry Count
  [12:8] Reserved — These bits are read as 00000. The write value should be 00000.
  [7:0] DVDYAD — Device I3C Dynamic Address
{0x226+8i} DATBAS{i}_BY_HL 8-bit (i=0..7) — Device Address Table Basic Register {i}
  [7:0] DVDYAD — Device I3C Dynamic Address
{0x227+8i} DATBAS{i}_BY_HH 8-bit (i=0..7) — Device Address Table Basic Register {i}
  [7] DVTYP — Device Type
    0=I3C: I3C Device; 1=I2C: I2C Device
  [6:5] DVNACK — Device NACK Retry Count
  [4:0] Reserved — These bits are read as 00000. The write value should be 00000.
